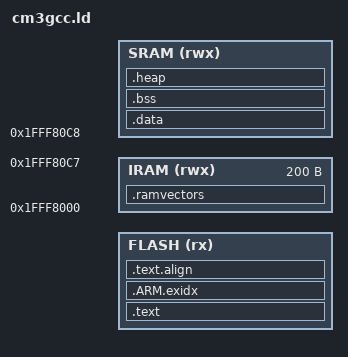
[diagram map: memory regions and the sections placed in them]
/*******************************************************************************
* File Name: Cm3Gcc.ld  
* Version `$CY_MAJOR_VERSION`.`$CY_MINOR_VERSION`
*
*  Description:
*  This Linker Descriptor file describes the memory layout of the PSoC5
*  device. The memory layout of the final binary and hex images as well as
*   the placement in PSoC5 memory is described.
*
*
*  Note:
*
*  romvectors:  Cypress default Interrupt sevice routine vector table.
*
*       This is the ISR vector table at bootup. Used only for the reset vector.
*
*
*  ramvectors:  Cypress ram interrupt service routine vector table.
*
*       This is the ISR vector table used by the application.
*
*
********************************************************************************
* Copyright 2008-2009, Cypress Semiconductor Corporation.  All rights reserved.
* You may use this file only in accordance with the license, terms, conditions, 
* disclaimers, and limitations in the end user license agreement accompanying 
* the software package with which this file was provided.
********************************************************************************/

/*******************************************************************************
 * The Custom Script Declaration section is used when you want create your own
 * custom linker script that is not generated by Cypress. To use this add the
 * following between the START and END sections below:
 *	#define CUSTOM_SCRIPT
 * This will cause the C preprocessor we use to ignore the standard linker script
 * below. In addition you should copy the linker script text below and paste it
 * into the section between the #START Custom Script and #END below. After doing
 * that you may modify the copied code any way you need to and it will be
 * remembered and used as long as you need it.
 ********************************************************************************/
/* `#START Custom Script Declaration` */

/* `#END` */

#if !defined(CUSTOM_SCRIPT)

MEMORY
{
    FLASH(rx) : ORIGIN =  `$PROJ_FIRST_FLS_BYTE`, LENGTH = `$FLASH_BYTES`
    IRAM(rwx) : ORIGIN = 0x1FFF8000, LENGTH = 0xC8
    SRAM(rwx) : ORIGIN = 0x1FFF80C8, LENGTH = (`$SRAM_BYTES` - 0xC8)
}

SECTIONS
{
    .text :
    {
        . = ALIGN(4);

        KEEP(*(.romvectors))
        *(.romvectors*)
        . = ALIGN(4);
        *(.dma_init)
        . = ALIGN(4);
        *(.text*)
        *(.rodata*)
        *(.jcr)
        *(.fini)
        *(.fini_array)
        *(.eh_frame)
        *(.init)
        *(.init_array)
        *(.ARM.extab*)
        KEEP(*(.bootloader)) /* necessary for bootloader's, but doesn't impact non-bootloaders */

    } > FLASH

    __exidx_start = .;
    .ARM.exidx :
    {
        *(.ARM.exidx* .gnu.linkonce.armexidx.*)

    } > FLASH
    __exidx_end = .;
    .text.align :
    {
        __etext = .;
        PROVIDE(_etext = .);

    } > FLASH

    .ramvectors (NOLOAD) :
    {
        . = ALIGN(4);
        *(.ramvectors)

    } > IRAM

    .data : AT (ADDR(.text) + SIZEOF(.text) + SIZEOF(.ARM.exidx) + SIZEOF(.text.align))
    {
        . = ALIGN(4);
        PROVIDE(_data = .);
        *(.data*)
        PROVIDE(_edata = .);

    } > SRAM

    .bss : AT (ADDR(.text) + SIZEOF(.text) + SIZEOF(.ARM.exidx) + SIZEOF(.text.align) + SIZEOF(.data))
    {
        PROVIDE(_bss = .);
        *(.bss*)
        *(COMMON)
        PROVIDE(_ebss = .);

        . = ALIGN(8);
        PROVIDE(_end = .);

    } > SRAM

    .heap : AT (ADDR(.text) + SIZEOF(.text) + SIZEOF(.ARM.exidx) + SIZEOF(.text.align) + SIZEOF(.data) + SIZEOF(.bss))
    {
        PROVIDE(_heap = .);
        PROVIDE(_stack = LENGTH(SRAM) - SIZEOF(.data) - SIZEOF(.bss));

    } > SRAM
}

#else

/* `#START Custom Script` */

/* `#END` */

#endif /* CUSTOM_SCRIPT */
